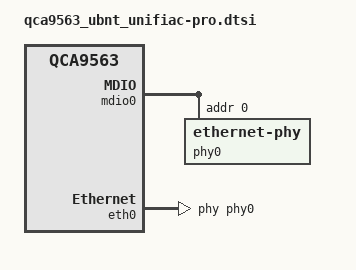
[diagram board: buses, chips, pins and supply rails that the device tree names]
// SPDX-License-Identifier: GPL-2.0-or-later OR MIT

#include "qca9563_ubnt_unifiac.dtsi"

/ {
	aliases {
		label-mac-device = &eth0;
	};
};

&mdio0 {
	status = "okay";
	phy-mask = <0>;

	phy0: ethernet-phy@0 {
		reg = <0>;
		phy-mode = "sgmii";
		qca,ar8327-initvals = <
			0x04 0x00080080 /* PORT0 PAD MODE CTRL */
			0x7c 0x0000007e /* PORT0_STATUS */
		>;
	};
};

&eth0 {
	status = "okay";

	nvmem-cells = <&macaddr_art_0>;
	nvmem-cell-names = "mac-address";
	phy-handle = <&phy0>;
};
